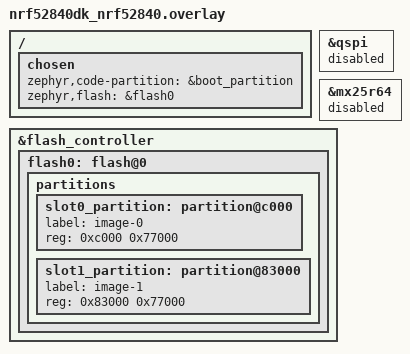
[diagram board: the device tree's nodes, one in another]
/**
	Copyright (c) 2025, Victor Chavez (vchavezb@protonmail.com)
	SPDX-License-Identifier: GPL-3.0-or-later
*/
/ {
	chosen {
		zephyr,code-partition = &boot_partition;
		zephyr,flash = &flash0;
	};
};

&qspi{
	status="disabled";
};

&mx25r64{
	status="disabled";
};

&flash_controller {
	flash0: flash@0 {
		partitions {
			slot0_partition: partition@c000 {
				label = "image-0";
				reg = < 0xc000 0x77000 >;
			};
			slot1_partition: partition@83000 {
				label = "image-1";
				reg = < 0x83000 0x77000 >;
			};
		};
	};
};

